AUTOSAR XML (schema 4-3-0)
standard types defined: uint64, uint8, uint64_DataConstr, uint8_DataConstr
package /ComponentTypes
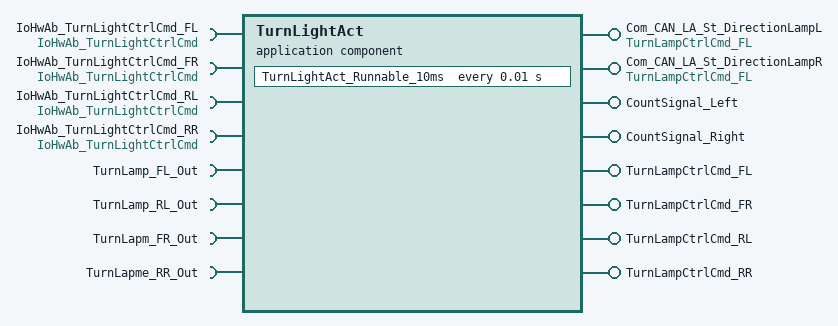
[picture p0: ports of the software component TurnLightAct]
  application sw component type TurnLightAct
    8 x provide port:
      Com_CAN_LA_St_DirectionLampL: nonqueued-sender-com-spec{data-element=TurnLampCtrlCmd_FL/u8_signal, init-value=0}, provided-interface=TurnLampCtrlCmd_FL
      Com_CAN_LA_St_DirectionLampR: nonqueued-sender-com-spec{data-element=TurnLampCtrlCmd_FL/u8_signal, init-value=0}, provided-interface=TurnLampCtrlCmd_FL
      CountSignal_Left: nonqueued-sender-com-spec{data-element=CountSignal_Left/u8_Signal, init-value=0}, provided-interface=CountSignal_Left
      CountSignal_Right: nonqueued-sender-com-spec{data-element=CountSignal_Right/u8_Signal, init-value=0}, provided-interface=CountSignal_Right
      TurnLampCtrlCmd_FL: nonqueued-sender-com-spec{data-element=TurnLampCtrlCmd_FL/u8_signal, init-value=0}, provided-interface=TurnLampCtrlCmd_FL
      TurnLampCtrlCmd_FR: nonqueued-sender-com-spec{data-element=u8_signa, init-value=0}, provided-interface=TurnLampCtrlCmd_FR
      TurnLampCtrlCmd_RL: nonqueued-sender-com-spec{data-element=TurnLampCtrlCmd_RL/u8_signal, init-value=0}, provided-interface=TurnLampCtrlCmd_RL
      TurnLampCtrlCmd_RR: nonqueued-sender-com-spec{data-element=TurnLampCtrlCmd_RR/u8_signal, init-value=0}, provided-interface=TurnLampCtrlCmd_RR
    8 x require port:
      IoHwAb_TurnLightCtrlCmd_FL: client-com-spec=Operation, required-interface=IoHwAb_TurnLightCtrlCmd
      IoHwAb_TurnLightCtrlCmd_FR: client-com-spec=Operation, required-interface=IoHwAb_TurnLightCtrlCmd
      IoHwAb_TurnLightCtrlCmd_RL: client-com-spec=Operation, required-interface=IoHwAb_TurnLightCtrlCmd
      IoHwAb_TurnLightCtrlCmd_RR: client-com-spec=Operation, required-interface=IoHwAb_TurnLightCtrlCmd
      TurnLamp_FL_Out: nonqueued-receiver-com-spec{data-element=TurnLamp_FL_Out/u8_Signal, filter=data-filter-type=ALWAYS, init-value=0}, required-interface=TurnLamp_FL_Out
      TurnLamp_RL_Out: nonqueued-receiver-com-spec{data-element=TurnLamp_RL_Out/u8_Signal, filter=data-filter-type=ALWAYS, init-value=0}, required-interface=TurnLamp_RL_Out
      TurnLapm_FR_Out: nonqueued-receiver-com-spec{data-element=TurnLapm_FR_Out/u8_Signal, filter=data-filter-type=ALWAYS, init-value=0}, required-interface=TurnLapm_FR_Out
      TurnLapme_RR_Out: nonqueued-receiver-com-spec{data-element=TurnLapme_RR_Out/u8_Signal, filter=data-filter-type=ALWAYS, init-value=0}, required-interface=TurnLapme_RR_Out
    behavior TurnLightAct_InternalBehavior
      timing event TMT_Runnable_10ms: start-on-event=TurnLightAct_Runnable_10ms, period=0.01
      runnable TurnLightAct_Runnable_10ms: minimum-start-interval=0.01
        data-receive-point-by-arguments:
          4 x access:
            REC_TurnLamp_FL_Out_u8_Signal: accessed-variable=TurnLamp_FL_Out.u8_Signal
            REC_TurnLamp_RL_Out_u8_Signal: accessed-variable=TurnLamp_RL_Out.u8_Signal
            REC_TurnLapm_FR_Out_u8_Signal: accessed-variable=TurnLapm_FR_Out.u8_Signal
            REC_TurnLapme_RR_Out_u8_Signal: accessed-variable=TurnLapme_RR_Out.u8_Signal
        data-send-points:
          8 x access:
            SEND_Com_CAN_LA_St_DirectionLampL_u8_signal: accessed-variable=Com_CAN_LA_St_DirectionLampL.u8_signal
            SEND_Com_CAN_LA_St_DirectionLampR_u8_signal: accessed-variable=Com_CAN_LA_St_DirectionLampR.u8_signal
            SEND_CountSignal_Left_u8_Signal: accessed-variable=CountSignal_Left.u8_Signal
            SEND_CountSignal_Right_u8_Signal: accessed-variable=CountSignal_Right.u8_Signal
            SEND_TurnLampCtrlCmd_FL_u8_signal: accessed-variable=TurnLampCtrlCmd_FL.u8_signal
            SEND_TurnLampCtrlCmd_FR_u8_signa: accessed-variable=TurnLampCtrlCmd_FR.u8_signa
            SEND_TurnLampCtrlCmd_RL_u8_signal: accessed-variable=TurnLampCtrlCmd_RL.u8_signal
            SEND_TurnLampCtrlCmd_RR_u8_signal: accessed-variable=TurnLampCtrlCmd_RR.u8_signal
        4 x sync call, all with timeout=0:
          SC_IoHwAb_TurnLightCtrlCmd_FL_Operation: operation=IoHwAb_TurnLightCtrlCmd_FL.Operation
          SC_IoHwAb_TurnLightCtrlCmd_FR_Operation: operation=IoHwAb_TurnLightCtrlCmd_FR.Operation
          SC_IoHwAb_TurnLightCtrlCmd_RL_Operation: operation=IoHwAb_TurnLightCtrlCmd_RL.Operation
          SC_IoHwAb_TurnLightCtrlCmd_RR_Operation: operation=IoHwAb_TurnLightCtrlCmd_RR.Operation
  swc implementation TurnLightAct_Implementation: behavior=TurnLightAct_InternalBehavior
    code-descriptors:
      code Default: artifact-descriptors=autosar-engineering-object={short-label=Default, category=SWSRC}
package /PortInterfaces
  client server interface IoHwAb_TurnLightCtrlCmd
    operation Operation
      arg CtrlCmd: type=uint8, direction=IN, server-argument-impl-policy=USE-ARGUMENT-TYPE
  10 x sender receiver interface:
    CountSignal_Left: invalidation-policy{data-element=CountSignal_Left/u8_Signal, handle-invalid=DONT-INVALIDATE}
      data u8_Signal: type=uint8
    CountSignal_Right: invalidation-policy{data-element=CountSignal_Right/u8_Signal, handle-invalid=DONT-INVALIDATE}
      data u8_Signal: type=uint8
    TurnLamp_FL_Out: invalidation-policy{data-element=TurnLamp_FL_Out/u8_Signal, handle-invalid=DONT-INVALIDATE}
      data u8_Signal: type=uint8
    TurnLamp_RL_Out: invalidation-policy{data-element=TurnLamp_RL_Out/u8_Signal, handle-invalid=DONT-INVALIDATE}
      data u8_Signal: type=uint8
    TurnLampCtrlCmd_FL: invalidation-policy{data-element=TurnLampCtrlCmd_FL/u8_signal, handle-invalid=DONT-INVALIDATE}
      data u8_signal: type=uint8
    TurnLampCtrlCmd_FR: invalidation-policy{data-element=u8_signa, handle-invalid=DONT-INVALIDATE}
      data u8_signa: type=uint8
    TurnLampCtrlCmd_RL: invalidation-policy{data-element=TurnLampCtrlCmd_RL/u8_signal, handle-invalid=DONT-INVALIDATE}
      data u8_signal: type=uint8
    TurnLampCtrlCmd_RR: invalidation-policy{data-element=TurnLampCtrlCmd_RR/u8_signal, handle-invalid=DONT-INVALIDATE}
      data u8_signal: type=uint64
    TurnLapm_FR_Out: invalidation-policy{data-element=TurnLapm_FR_Out/u8_Signal, handle-invalid=DONT-INVALIDATE}
      data u8_Signal: type=uint8
    TurnLapme_RR_Out: invalidation-policy{data-element=TurnLapme_RR_Out/u8_Signal, handle-invalid=DONT-INVALIDATE}
      data u8_Signal: type=uint8
